# dma_ctrl: IP-XACT component
VLNV tenstorrent.com:ocah:dma_ctrl:1.0

## Address spaces and blocks
dma_ctrl_mmap.dma_ctrl: base 'h0, range 'h138, width 32

## Registers
Registers are 32-bit, read-only, reset 0x0 unless marked. A register's access mark holds for its fields unless they carry their own. Offsets are from the block's base; lines under a group give offsets from that group; [hi:lo] are bit positions; {n}, {i} and the like mark numbered series; 'fields as' and 'values as' point back to an identical list; <NAME> marks a mode.

## dma_ctrl_mmap.dma_ctrl — Source, destination, length, and control registers for the iDMA data-mover engine.
Base 0x00000000
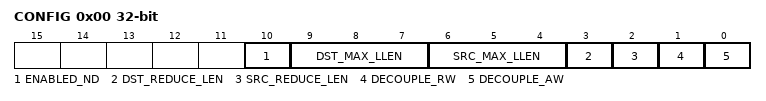
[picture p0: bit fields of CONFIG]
0x00 CONFIG rw
  [10] ENABLED_ND — Repetition enable. 1: the copy is performed NUM_REPETITIONS times, with SRC_STRIDE and DST_STRIDE added to the addresses between rows, modulo 2^56 and without an error when a row address wraps; set it for every transfer, including a linear copy with NUM_REPETITIONS = 1. 0: the repetition count is forced to zero, so the command completes with an error response, moves no data, and still retires its transfer ID.
  [9:7] DST_MAX_LLEN — Base-2 logarithm of the maximum write burst length in 64-bit beats, applied when DST_REDUCE_LEN is 1. A write burst does not cross a boundary aligned to 2^(DST_MAX_LLEN+3) bytes; 0 gives single-beat bursts. Ignored when DST_REDUCE_LEN is 0.
  [6:4] SRC_MAX_LLEN — Base-2 logarithm of the maximum read burst length in 64-bit beats, applied when SRC_REDUCE_LEN is 1. A read burst does not cross a boundary aligned to 2^(SRC_MAX_LLEN+3) bytes; 0 gives single-beat bursts. Ignored when SRC_REDUCE_LEN is 0.
  [3] DST_REDUCE_LEN — Destination burst-length reduction. 1: write bursts are limited by DST_MAX_LLEN. 0: a write burst is at most 256 beats and does not cross a 2 KiB-aligned boundary.
  [2] SRC_REDUCE_LEN — Source burst-length reduction. 1: read bursts are limited by SRC_MAX_LLEN. 0: a read burst is at most 256 beats and does not cross a 2 KiB-aligned boundary.
  [1] DECOUPLE_RW — Read/write decoupling. 0: read and write bursts are formed in lockstep, one write burst per read burst. 1: read and write bursts are formed and issued independently; this mode can deadlock.
  [0] DECOUPLE_AW — Write-address decoupling. 0: the write address of each burst is held until the first data beat of that burst is ready to be written. 1: write addresses are issued without waiting for write data.
{0x4+4i} STATUS_{i} (i=0..15)
  [9:0] BUSY — Status for the active stream: bits [7:0] each indicate readiness to accept another command, bit 8 reads 1 while a submitted command is queued or still being expanded into rows and falls when the backend accepts the last row of the last queued command, and bit 9 is zero. These bits do not report backend busy or prove transfer completion; use DONE for completed transfer IDs. Unused streams read zero.
{0x48+8i} NEXT_ID_{i} (i=0..15)
  [31:0] DATA — Reading this register starts the DMA transfer and returns its transfer ID. IDs start at 2, advance by one per command and never read 0; 0xFFFFFFFF reads as 1 from the cycle after it is reached. The descriptor is not validated: a command with zero repetitions, including one with CONFIG.ENABLED_ND clear, or with a length of 0 still retires without copying any data. A stream bank that is not implemented starts no transfer and returns 0.
{0xC8+4i} DONE_{i} (i=0..15)
  [31:0] DATA — Retirement counter for the stream. Resets to 1 and adds 1 per retirement, never reads 0, and reads 1 from the cycle after it reaches 0xFFFFFFFF. A command retires once, except that a command with CONFIG.ENABLED_ND set, a LENGTH of 0 and NUM_REPETITIONS N of 1 or more retires N times. The value therefore equals the ID NEXT_ID returned for the last retired command only while every earlier command retired once. Unused streams read zero.
0x108 DST_ADDRESS_LO rw
  [31:0] DATA — Destination address for DMA to write to, lower 32 bits
0x10C DST_ADDRESS_HI rw
  [31:0] DATA — Destination address for DMA to write to, upper 32 bits. Bits [31:24] (combined address bits [63:56]) are discarded, not checked; program them as zero.
0x110 SRC_ADDRESS_LO rw
  [31:0] DATA — Source address for DMA to read from, lower 32 bits.
0x114 SRC_ADDRESS_HI rw
  [31:0] DATA — Source address for DMA to read from, upper 32 bits. Bits [31:24] (combined address bits [63:56]) are discarded, not checked; program them as zero.
0x118 LENGTH_LO rw
  [31:0] DATA — Number of bytes to move, lower 32 bits.
0x11C LENGTH_HI rw
  [31:0] DATA — Number of bytes to move, upper 32 bits. Bits [31:24] (combined length bits [63:56]) are discarded, not checked; program them as zero.
0x120 DST_STRIDE_LO rw
  [31:0] DATA — Stride amount on destination address side, lower 32 bits
0x124 DST_STRIDE_HI rw
  [31:0] DATA — Stride amount on destination address side, upper 32 bits. Bits [31:24] (combined stride bits [63:56]) are discarded, not checked; program them as zero.
0x128 SRC_STRIDE_LO rw
  [31:0] DATA — Stride amount on source address side, lower 32 bits
0x12C SRC_STRIDE_HI rw
  [31:0] DATA — Stride amount on source address side, upper 32 bits. Bits [31:24] (combined stride bits [63:56]) are discarded, not checked; program them as zero.
0x130 NUM_REPETITIONS_LO rw
  [31:0] DATA — Number of rows to copy, including the first, lower 32 bits. SRC_STRIDE and DST_STRIDE are added to the addresses between rows. Takes effect only when CONFIG.ENABLED_ND is 1.
0x134 NUM_REPETITIONS_HI rw
  [31:0] DATA — Number of rows to copy, upper 32 bits. The DMA uses only the low 32 bits of the row count, so this register is discarded, not checked; program it as zero.

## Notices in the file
SPDX-License-Identifier: Apache-2.0
SPDX-FileCopyrightText: 2026 Tenstorrent USA, Inc.
